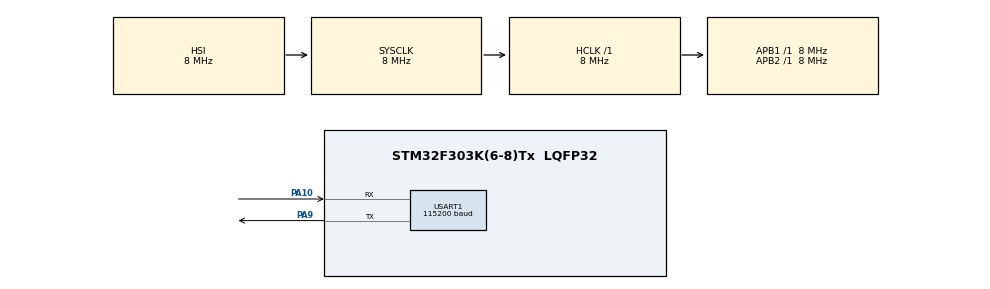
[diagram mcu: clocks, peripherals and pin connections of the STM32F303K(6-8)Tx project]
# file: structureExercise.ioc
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Mcu.Family=STM32F3
Mcu.Name=STM32F303K(6-8)Tx
Mcu.Package=LQFP32
NVIC.PriorityGroup=NVIC_PRIORITYGROUP_4
PA10.Mode=Asynchronous
PA10.Signal=USART1_RX
PA9.Mode=Asynchronous
PA9.Signal=USART1_TX
ProjectManager.HeapSize=0x200
ProjectManager.StackSize=0x400
ProjectManager.TargetToolchain=STM32CubeIDE
RCC.AHBFreq_Value=8000000
RCC.APB1Freq_Value=8000000
RCC.APB2Freq_Value=8000000
RCC.CortexFreq_Value=8000000
RCC.HSE_VALUE=8000000
RCC.HSI_VALUE=8000000
RCC.SYSCLKFreq_VALUE=8000000
USART1.BaudRate=115200
USART1.VirtualMode-Asynchronous=VM_ASYNC
board=custom

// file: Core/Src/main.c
/* USER CODE BEGIN Header */
/**
  ******************************************************************************
  * @file           : main.c
  * @brief          : Main program body
  ******************************************************************************
  * @attention
  *
  * Copyright (c) 2022 STMicroelectronics.
  * All rights reserved.
  *
  * This software is licensed under terms that can be found in the LICENSE file
  * in the root directory of this software component.
  * If no LICENSE file comes with this software, it is provided AS-IS.
  *
  ******************************************************************************
  */
/* USER CODE END Header */
#include "main.h"

/* USER CODE BEGIN Includes */
#include <stdio.h>
#include <console.h>

/* USER CODE END Includes */

 UART_HandleTypeDef huart1;

void SystemClock_Config(void);
static void MX_GPIO_Init(void);
static void MX_USART1_UART_Init(void);

int main(void)
{

  /* MCU Configuration--------------------------------------------------------*/

  /* Reset of all peripherals, Initializes the Flash interface and the Systick. */
  HAL_Init();

  /* Configure the system clock */
  SystemClock_Config();

  /* Initialize all configured peripherals */
  MX_GPIO_Init();
  MX_USART1_UART_Init();
  /* USER CODE BEGIN 2 */

//  Size of struct 4
  struct Packet{
  	  uint32_t crc:2;
  	  uint32_t status:1;
  	  uint32_t payload:12;
  	  uint32_t bat:3;
  	  uint32_t sensor:3;
  	  uint32_t longAddr:8;
  	  uint32_t shortAddr:2;
  	  uint32_t addrMode:1;
    };

//  Size of struct 10
//  struct Packet{
//	  uint8_t crc;
//	  uint8_t status;
//	  uint16_t payload;
//	  uint8_t bat;
//	  uint8_t sensor;
//	  uint8_t longAddr;
//	  uint8_t shortAddr;
//	  uint8_t addrMode;
//  };

  fflush(stdout);
  setvbuf( stdin, NULL, _IONBF, 0 );
  uint32_t packetValue;
  printf("Enter the 32bit packet value: \r\n");
  scanf("%x",&packetValue);
  printf("\r\n");

  struct Packet type;
//  Example:
// longAddr place 29 = 1+2+12+3+3+8 , 8bits -> FF
  type.crc = (uint8_t) (packetValue & 0x3); // 2 bit
  type.status = (uint8_t) ((packetValue >> 2) & 0x1); // 1 bit
  type.payload = (uint16_t) ((packetValue >> 3) & 0xFFF); // 12 bit
  type.bat = (uint8_t) ((packetValue >> 15) & 0x7); // 3 bit
  type.sensor = (uint8_t) ((packetValue >> 18) & 0x7); // 3 bit
  type.longAddr = (uint8_t) ((packetValue >> 21) & 0xFF); // 8 bit
  type.shortAddr = (uint8_t) ((packetValue >> 29) & 0x3); // 2 bit
  type.addrMode = (uint8_t) ((packetValue >> 31) & 0x1); // 1 bit

  printf("crc %#x \r\n", type.crc);
  printf("status %#x \r\n", type.status);
  printf("payload %#x \r\n", type.payload);
  printf("bat %#x \r\n", type.bat);
  printf("sensor %#x \r\n", type.sensor);
  printf("longAddr %#x \r\n", type.longAddr);
  printf("shortAddr %#x \r\n", type.shortAddr);
  printf("addrMode %#x \r\n", type.addrMode);

//  Size of struct
  printf("Size of struct is %u \r\n", sizeof(type));

  /* USER CODE END 2 */

  /* Infinite loop */
  while (1)
  {

  }
}

void SystemClock_Config(void)
{
  RCC_OscInitTypeDef RCC_OscInitStruct = {0};
  RCC_ClkInitTypeDef RCC_ClkInitStruct = {0};
  RCC_PeriphCLKInitTypeDef PeriphClkInit = {0};

  /** Initializes the RCC Oscillators according to the specified parameters
  * in the RCC_OscInitTypeDef structure.
  */
  RCC_OscInitStruct.OscillatorType = RCC_OSCILLATORTYPE_HSI;
  RCC_OscInitStruct.HSIState = RCC_HSI_ON;
  RCC_OscInitStruct.HSICalibrationValue = RCC_HSICALIBRATION_DEFAULT;
  RCC_OscInitStruct.PLL.PLLState = RCC_PLL_NONE;
  if (HAL_RCC_OscConfig(&RCC_OscInitStruct) != HAL_OK)
  {
    Error_Handler();
  }

  /** Initializes the CPU, AHB and APB buses clocks
  */
  RCC_ClkInitStruct.ClockType = RCC_CLOCKTYPE_HCLK|RCC_CLOCKTYPE_SYSCLK
                              |RCC_CLOCKTYPE_PCLK1|RCC_CLOCKTYPE_PCLK2;
  RCC_ClkInitStruct.SYSCLKSource = RCC_SYSCLKSOURCE_HSI;
  RCC_ClkInitStruct.AHBCLKDivider = RCC_SYSCLK_DIV1;
  RCC_ClkInitStruct.APB1CLKDivider = RCC_HCLK_DIV1;
  RCC_ClkInitStruct.APB2CLKDivider = RCC_HCLK_DIV1;

  if (HAL_RCC_ClockConfig(&RCC_ClkInitStruct, FLASH_LATENCY_0) != HAL_OK)
  {
    Error_Handler();
  }
  PeriphClkInit.PeriphClockSelection = RCC_PERIPHCLK_USART1;
  PeriphClkInit.Usart1ClockSelection = RCC_USART1CLKSOURCE_PCLK1;
  if (HAL_RCCEx_PeriphCLKConfig(&PeriphClkInit) != HAL_OK)
  {
    Error_Handler();
  }
}

static void MX_USART1_UART_Init(void)
{

  huart1.Instance = USART1;
  huart1.Init.BaudRate = 115200;
  huart1.Init.WordLength = UART_WORDLENGTH_8B;
  huart1.Init.StopBits = UART_STOPBITS_1;
  huart1.Init.Parity = UART_PARITY_NONE;
  huart1.Init.Mode = UART_MODE_TX_RX;
  huart1.Init.HwFlowCtl = UART_HWCONTROL_NONE;
  huart1.Init.OverSampling = UART_OVERSAMPLING_16;
  huart1.Init.OneBitSampling = UART_ONE_BIT_SAMPLE_DISABLE;
  huart1.AdvancedInit.AdvFeatureInit = UART_ADVFEATURE_NO_INIT;
  if (HAL_UART_Init(&huart1) != HAL_OK)
  {
    Error_Handler();
  }

}

static void MX_GPIO_Init(void)
{

  /* GPIO Ports Clock Enable */
  __HAL_RCC_GPIOA_CLK_ENABLE();

}

void Error_Handler(void)
{
  __disable_irq();
  while (1)
  {
  }
}
